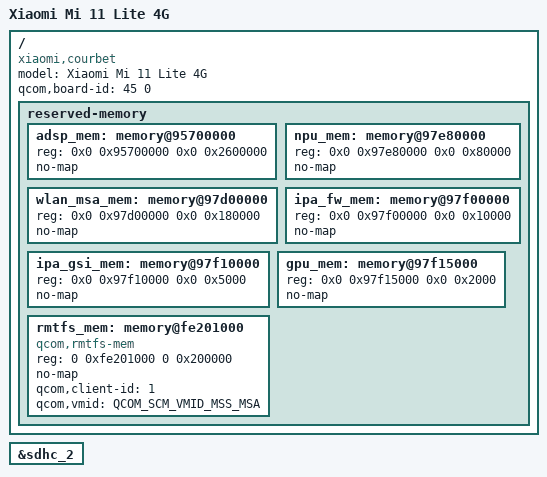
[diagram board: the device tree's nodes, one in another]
// SPDX-License-Identifier: BSD-3-Clause
/*
 * Xiaomi Mi 11 Lite 4G (courbet) board device tree source
 *
 * (C) Copyright 2024 Danila Tikhonov <danila@jiaxyga.com>
 */

 /dts-v1/;

#include "sm7150-xiaomi-common.dtsi"

/delete-node/ &adsp_mem;
/delete-node/ &wlan_msa_mem;
/delete-node/ &npu_mem;
/delete-node/ &ipa_fw_mem;
/delete-node/ &ipa_gsi_mem;
/delete-node/ &gpu_mem;

/ {
	model = "Xiaomi Mi 11 Lite 4G";
	compatible = "xiaomi,courbet", "qcom,sm7150";

	qcom,board-id = <45 0>;

	reserved-memory {
		adsp_mem: memory@95700000 {
			reg = <0x0 0x95700000 0x0 0x2600000>;
			no-map;
		};

		wlan_msa_mem: memory@97d00000 {
			reg = <0x0 0x97d00000 0x0 0x180000>;
			no-map;
		};

		npu_mem: memory@97e80000 {
			reg = <0x0 0x97e80000 0x0 0x80000>;
			no-map;
		};

		ipa_fw_mem: memory@97f00000 {
			reg = <0x0 0x97f00000 0x0 0x10000>;
			no-map;
		};

		ipa_gsi_mem: memory@97f10000 {
			reg = <0x0 0x97f10000 0x0 0x5000>;
			no-map;
		};

		gpu_mem: memory@97f15000 {
			reg = <0x0 0x97f15000 0x0 0x2000>;
			no-map;
		};

		rmtfs_mem: memory@fe201000 {
			compatible = "qcom,rmtfs-mem";
			reg = <0 0xfe201000 0 0x200000>;
			no-map;

			qcom,client-id = <1>;
			qcom,vmid = <QCOM_SCM_VMID_MSS_MSA>;
		};
	};
};

 &sdhc_2 {
         //status = "okay";
 };
